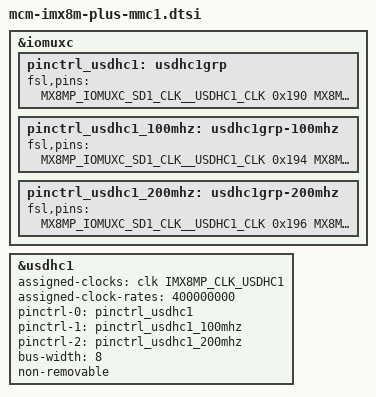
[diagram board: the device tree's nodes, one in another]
&iomuxc {

	pinctrl_usdhc1: usdhc1grp {
		fsl,pins = <
			MX8MP_IOMUXC_SD1_CLK__USDHC1_CLK	0x190
			MX8MP_IOMUXC_SD1_CMD__USDHC1_CMD	0x1d0
			MX8MP_IOMUXC_SD1_DATA0__USDHC1_DATA0	0x1d0
			MX8MP_IOMUXC_SD1_DATA1__USDHC1_DATA1	0x1d0
			MX8MP_IOMUXC_SD1_DATA2__USDHC1_DATA2	0x1d0
			MX8MP_IOMUXC_SD1_DATA3__USDHC1_DATA3	0x1d0
			MX8MP_IOMUXC_SD1_DATA4__USDHC1_DATA4	0x1d0
			MX8MP_IOMUXC_SD1_DATA5__USDHC1_DATA5	0x1d0
			MX8MP_IOMUXC_SD1_DATA6__USDHC1_DATA6	0x1d0
			MX8MP_IOMUXC_SD1_DATA7__USDHC1_DATA7	0x1d0
			MX8MP_IOMUXC_SD1_STROBE__USDHC1_STROBE	0x190
		>;
	};

	pinctrl_usdhc1_100mhz: usdhc1grp-100mhz {
		fsl,pins = <
			MX8MP_IOMUXC_SD1_CLK__USDHC1_CLK	0x194
			MX8MP_IOMUXC_SD1_CMD__USDHC1_CMD	0x1d4
			MX8MP_IOMUXC_SD1_DATA0__USDHC1_DATA0	0x1d4
			MX8MP_IOMUXC_SD1_DATA1__USDHC1_DATA1	0x1d4
			MX8MP_IOMUXC_SD1_DATA2__USDHC1_DATA2	0x1d4
			MX8MP_IOMUXC_SD1_DATA3__USDHC1_DATA3	0x1d4
			MX8MP_IOMUXC_SD1_DATA4__USDHC1_DATA4	0x1d4
			MX8MP_IOMUXC_SD1_DATA5__USDHC1_DATA5	0x1d4
			MX8MP_IOMUXC_SD1_DATA6__USDHC1_DATA6	0x1d4
			MX8MP_IOMUXC_SD1_DATA7__USDHC1_DATA7	0x1d4
			MX8MP_IOMUXC_SD1_STROBE__USDHC1_STROBE	0x194
		>;
	};

	pinctrl_usdhc1_200mhz: usdhc1grp-200mhz {
		fsl,pins = <
			MX8MP_IOMUXC_SD1_CLK__USDHC1_CLK	0x196
			MX8MP_IOMUXC_SD1_CMD__USDHC1_CMD	0x1d6
			MX8MP_IOMUXC_SD1_DATA0__USDHC1_DATA0	0x1d6
			MX8MP_IOMUXC_SD1_DATA1__USDHC1_DATA1	0x1d6
			MX8MP_IOMUXC_SD1_DATA2__USDHC1_DATA2	0x1d6
			MX8MP_IOMUXC_SD1_DATA3__USDHC1_DATA3	0x1d6
			MX8MP_IOMUXC_SD1_DATA4__USDHC1_DATA4	0x1d6
			MX8MP_IOMUXC_SD1_DATA5__USDHC1_DATA5	0x1d6
			MX8MP_IOMUXC_SD1_DATA6__USDHC1_DATA6	0x1d6
			MX8MP_IOMUXC_SD1_DATA7__USDHC1_DATA7	0x1d6
			MX8MP_IOMUXC_SD1_STROBE__USDHC1_STROBE	0x196
		>;
	};

};

&usdhc1 {
	assigned-clocks = <&clk IMX8MP_CLK_USDHC1>;
	assigned-clock-rates = <400000000>;
	pinctrl-names = "default", "state_100mhz", "state_200mhz";
	pinctrl-0 = <&pinctrl_usdhc1>;
	pinctrl-1 = <&pinctrl_usdhc1_100mhz>;
	pinctrl-2 = <&pinctrl_usdhc1_200mhz>;
	bus-width = <8>;
	non-removable;
	status = "okay";
};

